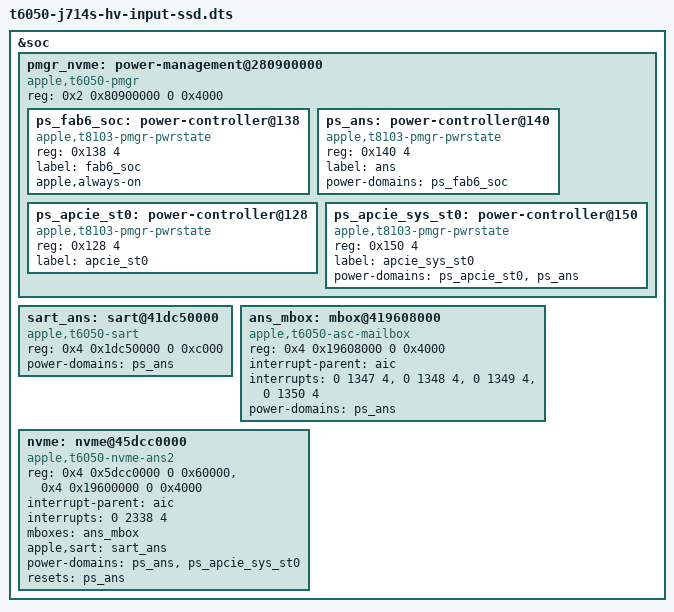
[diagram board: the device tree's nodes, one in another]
// Input baseline plus the previously mapped ANS stack. RAM root stays primary.
#include "t6050-j714s-hv-input-sid0.dts"

&soc {
	// These four guest power states MUST be shadowed by --prepare-ans.
	// Host preparation activates the exact board-derived domains beforehand.
	pmgr_nvme: power-management@280900000 {
		compatible = "apple,t6050-pmgr", "apple,t8103-pmgr", "syscon", "simple-mfd";
		#address-cells = <1>;
		#size-cells = <1>;
		reg = <0x2 0x80900000 0 0x4000>;
		ps_fab6_soc: power-controller@138 {
			compatible = "apple,t8103-pmgr-pwrstate";
			reg = <0x138 4>;
			#power-domain-cells = <0>;
			#reset-cells = <0>;
			label = "fab6_soc";
			apple,always-on;
		};
		ps_ans: power-controller@140 {
			compatible = "apple,t8103-pmgr-pwrstate";
			reg = <0x140 4>;
			#power-domain-cells = <0>;
			#reset-cells = <0>;
			label = "ans";
			power-domains = <&ps_fab6_soc>;
		};
		ps_apcie_st0: power-controller@128 {
			compatible = "apple,t8103-pmgr-pwrstate";
			reg = <0x128 4>;
			#power-domain-cells = <0>;
			#reset-cells = <0>;
			label = "apcie_st0";
		};
		ps_apcie_sys_st0: power-controller@150 {
			compatible = "apple,t8103-pmgr-pwrstate";
			reg = <0x150 4>;
			#power-domain-cells = <0>;
			#reset-cells = <0>;
			label = "apcie_sys_st0";
			power-domains = <&ps_apcie_st0>, <&ps_ans>;
		};
	};
	sart_ans: sart@41dc50000 {
		// Existing live-kit SARTv4 translation supplies this v3 guest ABI.
		compatible = "apple,t6050-sart", "apple,t6000-sart";
		reg = <0x4 0x1dc50000 0 0xc000>;
		power-domains = <&ps_ans>;
	};
	ans_mbox: mbox@419608000 {
		compatible = "apple,t6050-asc-mailbox", "apple,asc-mailbox-v4";
		reg = <0x4 0x19608000 0 0x4000>;
		interrupt-parent = <&aic>;
		interrupts = <0 1347 4>, <0 1348 4>, <0 1349 4>, <0 1350 4>;
		interrupt-names = "send-empty", "send-not-empty", "recv-empty", "recv-not-empty";
		#mbox-cells = <0>;
		power-domains = <&ps_ans>;
	};
	nvme: nvme@45dcc0000 {
		// ANS2 ABI with M4+ secure BAR split, translated by existing live kit.
		compatible = "apple,t6050-nvme-ans2", "apple,t8103-nvme-ans2";
		reg = <0x4 0x5dcc0000 0 0x60000>, <0x4 0x19600000 0 0x4000>;
		reg-names = "nvme", "ans";
		interrupt-parent = <&aic>;
		interrupts = <0 2338 4>;
		mboxes = <&ans_mbox>;
		apple,sart = <&sart_ans>;
		power-domains = <&ps_ans>, <&ps_apcie_sys_st0>;
		power-domain-names = "ans", "apcie0";
		resets = <&ps_ans>;
	};
};
